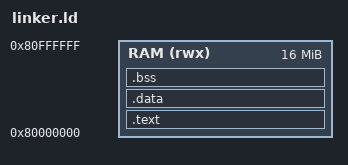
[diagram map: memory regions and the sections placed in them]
ENTRY(_start)

MEMORY {
    RAM (rwx) : ORIGIN = 0x80000000, LENGTH = 16M
}

SECTIONS {
    .text : {
        *(.text.start)
        *(.text*)
    } > RAM

    .data : {
        *(.data*)
    } > RAM

    .bss : {
        *(COMMON)
        *(.bss*)
    } > RAM
}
